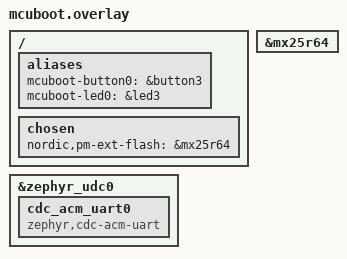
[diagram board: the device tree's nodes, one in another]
/ {
  aliases {
		mcuboot-button0 = &button3;
		mcuboot-led0 = &led3;
  };
};

&mx25r64 {
	status = "okay";
};

/ {
	chosen {
		nordic,pm-ext-flash = &mx25r64;
	};
};

&zephyr_udc0 {
	cdc_acm_uart0: cdc_acm_uart0 {
		compatible = "zephyr,cdc-acm-uart";
	};
};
